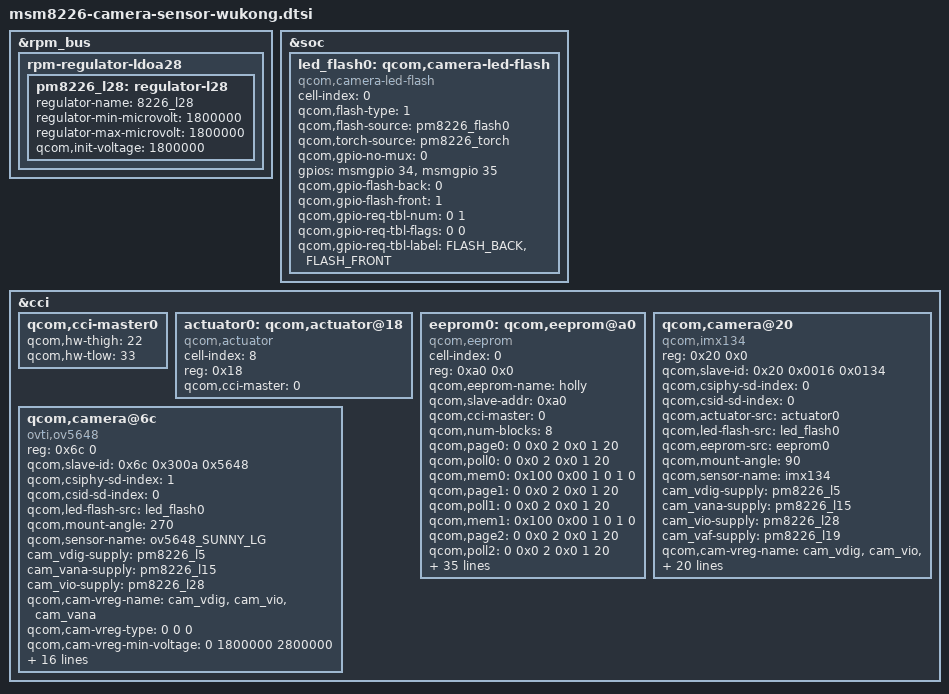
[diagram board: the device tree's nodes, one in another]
/*
 *  Copyright (C) 2014 Sony Mobile Communications Inc.
 *  All rights, including trade secret rights, reserved.
 */

&rpm_bus {
	rpm-regulator-ldoa28 {
		status = "okay";
		pm8226_l28: regulator-l28 {
			regulator-name = "8226_l28";
			regulator-min-microvolt = <1800000>;
			regulator-max-microvolt = <1800000>;
			qcom,init-voltage = <1800000>;
			status = "okay";
		};
	};
};

&soc {

	led_flash0: qcom,camera-led-flash {
		cell-index = <0>;
		compatible = "qcom,camera-led-flash";
		qcom,flash-type = <1>;
		qcom,flash-source = <&pm8226_flash0>;
		qcom,torch-source = <&pm8226_torch>;
		qcom,gpio-no-mux = <0>;
		gpios = <&msmgpio 34 0>,
			<&msmgpio 35 0>;
		qcom,gpio-flash-back = <0>;
		qcom,gpio-flash-front = <1>;
		qcom,gpio-req-tbl-num = <0 1>;
		qcom,gpio-req-tbl-flags = <0 0>;
		qcom,gpio-req-tbl-label = "FLASH_BACK",
			"FLASH_FRONT";
	};
};

&cci {
	qcom,cci-master0 {
		qcom,hw-thigh = <22>;
		qcom,hw-tlow = <33>;
	};

	actuator0: qcom,actuator@18 {
		cell-index = <8>;
		reg = <0x18>;
		compatible = "qcom,actuator";
		qcom,cci-master = <0>;
	};

	eeprom0: qcom,eeprom@a0 {
		cell-index = <0>;
		reg = <0xa0 0x0>;
		qcom,eeprom-name = "holly";
		compatible = "qcom,eeprom";
		qcom,slave-addr = <0xa0>;
		qcom,cci-master = <0>;
		qcom,num-blocks = <8>;
		qcom,page0 = <0 0x0 2 0x0 1 20>;
		qcom,poll0 = <0 0x0 2 0x0 1 20>;
		qcom,mem0 = <0x100 0x00 1 0 1 0>;
		qcom,page1 = <0 0x0 2 0x0 1 20>;
		qcom,poll1 = <0 0x0 2 0x0 1 20>;
		qcom,mem1 = <0x100 0x00 1 0 1 0>;
		qcom,page2 = <0 0x0 2 0x0 1 20>;
		qcom,poll2 = <0 0x0 2 0x0 1 20>;
		qcom,mem2 = <0x100 0x00 1 0 1 0>;
		qcom,page3 = <0 0x0 2 0x0 1 20>;
		qcom,poll3 = <0 0x0 2 0x0 1 20>;
		qcom,mem3 = <0x100 0x00 1 0 1 0>;
		qcom,page4 = <0 0x0 2 0x0 1 20>;
		qcom,poll4 = <0 0x0 2 0x0 1 20>;
		qcom,mem4 = <0x100 0x00 1 0 1 0>;
		qcom,page5 = <0 0x0 2 0x0 1 20>;
		qcom,poll5 = <0 0x0 2 0x0 1 20>;
		qcom,mem5 = <0x100 0x00 1 0 1 0>;
		qcom,page6 = <0 0x0 2 0x0 1 20>;
		qcom,poll6 = <0 0x0 2 0x0 1 20>;
		qcom,mem6 = <0x100 0x00 1 0 1 0>;
		qcom,page7 = <0 0x0 2 0x0 1 20>;
		qcom,poll7 = <0 0x0 2 0x0 1 20>;
		qcom,mem7 = <0x100 0x00 1 0 1 0>;
		cam_vdig-supply = <&pm8226_l5>;
		cam_vio-supply = <&pm8226_l28>;
		qcom,cam-vreg-name = "cam_vdig","cam_vio";
		qcom,cam-vreg-type = <0 0>;
		qcom,cam-vreg-min-voltage = <1125000 1800000>;
		qcom,cam-vreg-max-voltage = <1125000 1800000>;
		qcom,cam-vreg-op-mode = <200000 200000>;
		qcom,gpio-no-mux = <0>;
		gpios = <&msmgpio 26 0>,
			<&msmgpio 37 0>;
		qcom,gpio-reset = <1>;
		qcom,gpio-req-tbl-num = <0 1>;
		qcom,gpio-req-tbl-flags = <1 1>;
		qcom,gpio-req-tbl-label = "CAMIF_MCLK",
			"CAM_RESET1";
		qcom,cam-power-seq-type = "sensor_vreg","sensor_vreg";
		qcom,cam-power-seq-val = "cam_vdig","cam_vio";
		qcom,cam-power-seq-cfg-val = <1 1>;
		qcom,cam-power-seq-delay = <1 1>;
	};

	qcom,camera@20 {
		compatible = "qcom,imx134";
		reg = <0x20 0x0>;
		status = "ok";
		qcom,slave-id = <0x20 0x0016 0x0134>;
		qcom,csiphy-sd-index = <0>;
		qcom,csid-sd-index = <0>;
		qcom,actuator-src = <&actuator0>;
		qcom,led-flash-src = <&led_flash0>;
		qcom,eeprom-src = <&eeprom0>;
		qcom,mount-angle = <90>;
		qcom,sensor-name = "imx134";
		cam_vdig-supply = <&pm8226_l5>;
		cam_vana-supply = <&pm8226_l15>;
		cam_vio-supply = <&pm8226_l28>;
		cam_vaf-supply = <&pm8226_l19>;
		qcom,cam-vreg-name = "cam_vdig", "cam_vio", "cam_vana";
		qcom,cam-vreg-type = <0 0 0 >;
		qcom,cam-vreg-min-voltage = <1125000 1800000 2800000>;
		qcom,cam-vreg-max-voltage = <1125000 1800000 2800000>;
		qcom,cam-vreg-op-mode = <200000 200000 100000>;
		qcom,gpio-no-mux = <0>;
		gpios = <&msmgpio 26 0>, <&msmgpio 37 0>;
		qcom,gpio-reset = <1>;
		qcom,gpio-req-tbl-num = <0 1>;
		qcom,gpio-req-tbl-flags = <1 0>;
		qcom,gpio-req-tbl-label = "CAMIF_MCLK", "CAM_RESET1";
		qcom,csi-lane-assign = <0x4320>;
		qcom,csi-lane-mask = <0x1F>;
		qcom,sensor-position = <0>;
		qcom,sensor-mode = <0>;
		qcom,sensor-type = <0>;
		qcom,cci-master = <0>;
	};

	qcom,camera@6c {
		compatible = "ovti,ov5648";
		reg = <0x6c 0>;
		status = "ok";
		qcom,slave-id = <0x6c 0x300a 0x5648>;
		qcom,csiphy-sd-index = <1>;
		qcom,csid-sd-index = <0>;
		qcom,led-flash-src = <&led_flash0>;
		qcom,mount-angle = <270>;
		qcom,sensor-name = "ov5648_SUNNY_LG";
		cam_vdig-supply = <&pm8226_l5>;
		cam_vana-supply = <&pm8226_l15>;
		cam_vio-supply = <&pm8226_l28>;
		qcom,cam-vreg-name = "cam_vdig", "cam_vio", "cam_vana";
		qcom,cam-vreg-type = <0 0 0>;
		qcom,cam-vreg-min-voltage = <0 1800000 2800000>;
		qcom,cam-vreg-max-voltage = <0 1800000 2800000>;
		qcom,cam-vreg-op-mode = <0 200000 80000>;
		qcom,gpio-no-mux = <0>;
		gpios = <&msmgpio 26 0>,
			<&msmgpio 28 0>,
			<&msmgpio 36 0>;
		qcom,gpio-vio = <2>;
		qcom,gpio-reset = <1>;
		qcom,gpio-req-tbl-num = <0 1 2>;
		qcom,gpio-req-tbl-flags = <1 0 0>;
		qcom,gpio-req-tbl-label = "CAMIF_MCLK",
					  "CAM_VIO",
					  "CAM_RESET1";
		qcom,csi-lane-assign = <0x4320>;
		qcom,csi-lane-mask = <0x3>;
		qcom,sensor-position = <1>;
		qcom,sensor-mode = <1>;
		qcom,sensor-type = <0>;
		qcom,cci-master = <0>;
	};
};
